AUTOSAR XML (schema 00046)
package /ComponentTypes
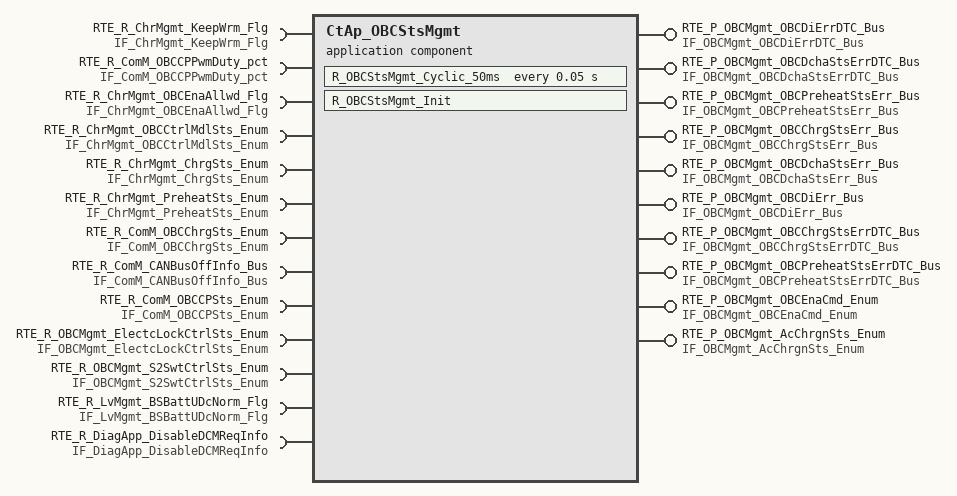
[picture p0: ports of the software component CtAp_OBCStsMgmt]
  application sw component type CtAp_OBCStsMgmt
    provide port RTE_P_OBCMgmt_OBCDiErrDTC_Bus: nonqueued-sender-com-spec{data-element=tec_OBCMgmt_OBCDiErrDTC_Bus, init-value=fields=[OBCMgmt_MonStatOBCDiErrDTC:0, OBCMgmt_MonResOBCDiErrDTC:0, OBCMgmt_ErrStatOBCDiErrDTC:0, OBCMgmt_ErrResOBCDiErrDTC:0]}, provided-interface=IF_OBCMgmt_OBCDiErrDTC_Bus
    require port RTE_R_ChrMgmt_KeepWrm_Flg: nonqueued-receiver-com-spec{data-element=tec_ChrMgmt_KeepWrm_Flg, filter=data-filter-type=ALWAYS, init-value=0}, required-interface=IF_ChrMgmt_KeepWrm_Flg
    provide port RTE_P_OBCMgmt_OBCDchaStsErrDTC_Bus: nonqueued-sender-com-spec{data-element=tec_OBCMgmt_OBCDchaStsErrDTC_Bus, init-value=fields=[OBCMgmt_MonStatOBCDchaStsErrDTC:0, OBCMgmt_MonResOBCDchaStsErrDTC:0, OBCMgmt_ErrStatOBCDchaStsErrDTC:0, OBCMgmt_ErrResOBCDchaStsErrDTC:0]}, provided-interface=IF_OBCMgmt_OBCDchaStsErrDTC_Bus
    provide port RTE_P_OBCMgmt_OBCPreheatStsErr_Bus: nonqueued-sender-com-spec{data-element=tec_OBCMgmt_OBCPreheatStsErr_Bus, init-value=fields=[OBCMgmt_MonStatOBCPreheatStsErr:0, OBCMgmt_MonResOBCPreheatStsErr:0, OBCMgmt_ErrStatOBCPreheatStsErr:0, OBCMgmt_ErrResOBCPreheatStsErr:0]}, provided-interface=IF_OBCMgmt_OBCPreheatStsErr_Bus
    require port RTE_R_ComM_OBCCPPwmDuty_pct: nonqueued-receiver-com-spec{data-element=tec_ComM_OBCCPPwmDuty_pct, filter=data-filter-type=ALWAYS, init-value=0}, required-interface=IF_ComM_OBCCPPwmDuty_pct
    provide port RTE_P_OBCMgmt_OBCChrgStsErr_Bus: nonqueued-sender-com-spec{data-element=tec_OBCMgmt_OBCChrgStsErr_Bus, init-value=fields=[OBCMgmt_MonStatOBCChrgStsErr:0, OBCMgmt_MonResOBCChrgStsErr:0, OBCMgmt_ErrStatOBCChrgStsErr:0, OBCMgmt_ErrResOBCChrgStsErr:0]}, provided-interface=IF_OBCMgmt_OBCChrgStsErr_Bus
    require port RTE_R_ChrMgmt_OBCEnaAllwd_Flg: nonqueued-receiver-com-spec{data-element=tec_ChrMgmt_OBCEnaAllwd_Flg, filter=data-filter-type=ALWAYS, init-value=0}, required-interface=IF_ChrMgmt_OBCEnaAllwd_Flg
    4 x provide port:
      RTE_P_OBCMgmt_OBCDchaStsErr_Bus: nonqueued-sender-com-spec{data-element=tec_OBCMgmt_OBCDchaStsErr_Bus, init-value=fields=[OBCMgmt_MonStatOBCDchaStsErr:0, OBCMgmt_MonResOBCDchaStsErr:0, OBCMgmt_ErrStatOBCDchaStsErr:0, OBCMgmt_ErrResOBCDchaStsErr:0]}, provided-interface=IF_OBCMgmt_OBCDchaStsErr_Bus
      RTE_P_OBCMgmt_OBCDiErr_Bus: nonqueued-sender-com-spec{data-element=tec_OBCMgmt_OBCDiErr_Bus, init-value=fields=[OBCMgmt_MonStatOBCDiErr:0, OBCMgmt_MonResOBCDiErr:0, OBCMgmt_ErrStatOBCDiErr:0, OBCMgmt_ErrResOBCDiErr:0]}, provided-interface=IF_OBCMgmt_OBCDiErr_Bus
      RTE_P_OBCMgmt_OBCChrgStsErrDTC_Bus: nonqueued-sender-com-spec{data-element=tec_OBCMgmt_OBCChrgStsErrDTC_Bus, init-value=fields=[OBCMgmt_MonStatOBCChrgStsErrDTC:0, OBCMgmt_MonResOBCChrgStsErrDTC:0, OBCMgmt_ErrStatOBCChrgStsErrDTC:0, OBCMgmt_ErrResOBCChrgStsErrDTC:0]}, provided-interface=IF_OBCMgmt_OBCChrgStsErrDTC_Bus
      RTE_P_OBCMgmt_OBCPreheatStsErrDTC_Bus: nonqueued-sender-com-spec{data-element=tec_OBCMgmt_OBCPreheatStsErrDTC_Bus, init-value=fields=[OBCMgmt_MonStatOBCPreheatStsErrDTC:0, OBCMgmt_MonResOBCPreheatStsErrDTC:0, OBCMgmt_ErrStatOBCPreheatStsErrDTC:0, OBCMgmt_ErrResOBCPreheatStsErrDTC:0]}, provided-interface=IF_OBCMgmt_OBCPreheatStsErrDTC_Bus
    require port RTE_R_ChrMgmt_OBCCtrlMdlSts_Enum: nonqueued-receiver-com-spec{data-element=tec_ChrMgmt_OBCCtrlMdlSts_Enum, filter=data-filter-type=ALWAYS, init-value=0}, required-interface=IF_ChrMgmt_OBCCtrlMdlSts_Enum
    require port RTE_R_ChrMgmt_ChrgSts_Enum: nonqueued-receiver-com-spec{data-element=tec_ChrMgmt_ChrgSts_Enum, filter=data-filter-type=ALWAYS, init-value=0}, required-interface=IF_ChrMgmt_ChrgSts_Enum
    provide port RTE_P_OBCMgmt_OBCEnaCmd_Enum: nonqueued-sender-com-spec{data-element=tec_OBCMgmt_OBCEnaCmd_Enum, init-value=0}, provided-interface=IF_OBCMgmt_OBCEnaCmd_Enum
    provide port RTE_P_OBCMgmt_AcChrgnSts_Enum: nonqueued-sender-com-spec{data-element=tec_OBCMgmt_AcChrgnSts_Enum, init-value=0}, provided-interface=IF_OBCMgmt_AcChrgnSts_Enum
    8 x require port:
      RTE_R_ChrMgmt_PreheatSts_Enum: nonqueued-receiver-com-spec{data-element=tec_ChrMgmt_PreheatSts_Enum, filter=data-filter-type=ALWAYS, init-value=0}, required-interface=IF_ChrMgmt_PreheatSts_Enum
      RTE_R_ComM_OBCChrgSts_Enum: nonqueued-receiver-com-spec{data-element=tec_ComM_OBCChrgSts_Enum, filter=data-filter-type=ALWAYS, init-value=0}, required-interface=IF_ComM_OBCChrgSts_Enum
      RTE_R_ComM_CANBusOffInfo_Bus: required-interface=IF_ComM_CANBusOffInfo_Bus
        required-com-specs:
          data-element=tec_ComM_EPTCANBusOffInfo_Bus, filter=data-filter-type=ALWAYS, init-value=fields=[ComM_MonStatEPTCANBusOffInfo:0, ComM_MonResEPTCANBusOffInfo:0, ComM_ErrStatEPTCANBusOffInfo:0, ComM_ErrResEPTCANBusOffInfo:0]
          data-element=tec_ComM_CHCANBusOffInfo_Bus, filter=data-filter-type=ALWAYS, init-value=fields=[ComM_MonStatCHCANBusOffInfo:0, ComM_MonResCHCANBusOffInfo:0, ComM_ErrStatCHCANBusOffInfo:0, ComM_ErrResCHCANBusOffInfo:0]
          data-element=tec_ComM_EPTCANBusOffDTCInfo_Bus, filter=data-filter-type=ALWAYS, init-value=fields=[ComM_MonStatEPTCANBusOffDTCInfo:0, ComM_MonResEPTCANBusOffDTCInfo:0, ComM_ErrStatEPTCANBusOffDTCInfo:0, ComM_ErrResEPTCANBusOffDTCInfo:0]
          data-element=tec_ComM_CHCANBusOffDTCInfo_Bus, filter=data-filter-type=ALWAYS, init-value=fields=[ComM_MonStatCHCANBusOffDTCInfo:0, ComM_MonResCHCANBusOffDTCInfo:0, ComM_ErrStatCHCANBusOffDTCInfo:0, ComM_ErrResCHCANBusOffDTCInfo:0]
          data-element=tec_ComM_DCCANBusOffDTCInfo_Bus, init-value=fields=[ComM_MonStatDCCANDTCBusOffInfo:0, ComM_MonResDCCANDTCBusOffInfo:0, ComM_ErrStatDCCANDTCBusOffInfo:0, ComM_ErrResDCCANDTCBusOffInfo:0]
          data-element=tec_ComM_DCCANBusOffInfo_Bus, init-value=fields=[ComM_MonStatDCCANBusOffInfo:0, ComM_MonResDCCANBusOffInfo:0, ComM_ErrStatDCCANBusOffInfo:0, ComM_ErrResDCCANBusOffInfo:0]
      RTE_R_ComM_OBCCPSts_Enum: nonqueued-receiver-com-spec{data-element=tec_ComM_OBCCPSts_Enum, filter=data-filter-type=ALWAYS, init-value=0}, required-interface=IF_ComM_OBCCPSts_Enum
      RTE_R_OBCMgmt_ElectcLockCtrlSts_Enum: nonqueued-receiver-com-spec{data-element=tec_OBCMgmt_ElectcLockCtrlSts_Enum, filter=data-filter-type=ALWAYS, init-value=0}, required-interface=IF_OBCMgmt_ElectcLockCtrlSts_Enum
      RTE_R_OBCMgmt_S2SwtCtrlSts_Enum: nonqueued-receiver-com-spec{data-element=tec_OBCMgmt_S2SwtCtrlSts_Enum, filter=data-filter-type=ALWAYS, init-value=0}, required-interface=IF_OBCMgmt_S2SwtCtrlSts_Enum
      RTE_R_LvMgmt_BSBattUDcNorm_Flg: nonqueued-receiver-com-spec{data-element=tec_LvMgmt_BSBattUDcNorm_Flg, filter=data-filter-type=ALWAYS, init-value=0}, required-interface=IF_LvMgmt_BSBattUDcNorm_Flg
      RTE_R_DiagApp_DisableDCMReqInfo: nonqueued-receiver-com-spec{data-element=tec_DiagApp_DisableDCMReqInfo, filter=data-filter-type=ALWAYS, init-value=0}, required-interface=IF_DiagApp_DisableDCMReqInfo
    behavior CtAp_OBCStsMgmt_InternalBehavior
      timing event TMT_R_OBCStsMgmt_Cyclic_50ms: start-on-event=R_OBCStsMgmt_Cyclic_50ms, period=0.05
      init event CtAp_OBCStsMgmt_InitEvent: start-on-event=R_OBCStsMgmt_Init
      runnable R_OBCStsMgmt_Cyclic_50ms
        data-receive-point-by-arguments:
          13 x access:
            REC_RTE_R_ChrMgmt_ChrgSts_Enum_tec_ChrMgmt_ChrgSts_Enum: accessed-variable=RTE_R_ChrMgmt_ChrgSts_Enum.tec_ChrMgmt_ChrgSts_Enum
            REC_RTE_R_ChrMgmt_KeepWrm_Flg_tec_ChrMgmt_KeepWrm_Flg: accessed-variable=RTE_R_ChrMgmt_KeepWrm_Flg.tec_ChrMgmt_KeepWrm_Flg
            REC_RTE_R_ChrMgmt_OBCCtrlMdlSts_Enum_tec_ChrMgmt_OBCCtrlMdlSts_Enum: accessed-variable=RTE_R_ChrMgmt_OBCCtrlMdlSts_Enum.tec_ChrMgmt_OBCCtrlMdlSts_Enum
            REC_RTE_R_ChrMgmt_OBCEnaAllwd_Flg_tec_ChrMgmt_OBCEnaAllwd_Flg: accessed-variable=RTE_R_ChrMgmt_OBCEnaAllwd_Flg.tec_ChrMgmt_OBCEnaAllwd_Flg
            REC_RTE_R_ChrMgmt_PreheatSts_Enum_tec_ChrMgmt_PreheatSts_Enum: accessed-variable=RTE_R_ChrMgmt_PreheatSts_Enum.tec_ChrMgmt_PreheatSts_Enum
            REC_RTE_R_ComM_CANBusOffInfo_Bus_tec_ComM_EPTCANBusOffInfo_Bus: accessed-variable=RTE_R_ComM_CANBusOffInfo_Bus.tec_ComM_EPTCANBusOffInfo_Bus
            REC_RTE_R_ComM_OBCCPPwmDuty_pct_tec_ComM_OBCCPPwmDuty_pct: accessed-variable=RTE_R_ComM_OBCCPPwmDuty_pct.tec_ComM_OBCCPPwmDuty_pct
            REC_RTE_R_ComM_OBCCPSts_Enum_tec_ComM_OBCCPSts_Enum: accessed-variable=RTE_R_ComM_OBCCPSts_Enum.tec_ComM_OBCCPSts_Enum
            REC_RTE_R_ComM_OBCChrgSts_Enum_tec_ComM_OBCChrgSts_Enum: accessed-variable=RTE_R_ComM_OBCChrgSts_Enum.tec_ComM_OBCChrgSts_Enum
            REC_RTE_R_OBCMgmt_ElectcLockCtrlSts_Enum_tec_OBCMgmt_ElectcLockCtrlSts_Enum: accessed-variable=RTE_R_OBCMgmt_ElectcLockCtrlSts_Enum.tec_OBCMgmt_ElectcLockCtrlSts_Enum
            REC_RTE_R_LvMgmt_BSBattUDcNorm_Flg_tec_LvMgmt_BSBattUDcNorm_Flg: accessed-variable=RTE_R_LvMgmt_BSBattUDcNorm_Flg.tec_LvMgmt_BSBattUDcNorm_Flg
            REC_RTE_R_OBCMgmt_S2SwtCtrlSts_Enum_tec_OBCMgmt_S2SwtCtrlSts_Enum: accessed-variable=RTE_R_OBCMgmt_S2SwtCtrlSts_Enum.tec_OBCMgmt_S2SwtCtrlSts_Enum
            REC_RTE_R_DiagApp_DisableDCMReqInfo_tec_DiagApp_DisableDCMReqInfo: accessed-variable=RTE_R_DiagApp_DisableDCMReqInfo.tec_DiagApp_DisableDCMReqInfo
        data-send-points:
          10 x access:
            SEND_RTE_P_OBCMgmt_AcChrgnSts_Enum_tec_OBCMgmt_AcChrgnSts_Enum: accessed-variable=RTE_P_OBCMgmt_AcChrgnSts_Enum.tec_OBCMgmt_AcChrgnSts_Enum
            SEND_RTE_P_OBCMgmt_OBCChrgStsErrDTC_Bus_tec_OBCMgmt_OBCChrgStsErrDTC_Bus: accessed-variable=RTE_P_OBCMgmt_OBCChrgStsErrDTC_Bus.tec_OBCMgmt_OBCChrgStsErrDTC_Bus
            SEND_RTE_P_OBCMgmt_OBCChrgStsErr_Bus_tec_OBCMgmt_OBCChrgStsErr_Bus: accessed-variable=RTE_P_OBCMgmt_OBCChrgStsErr_Bus.tec_OBCMgmt_OBCChrgStsErr_Bus
            SEND_RTE_P_OBCMgmt_OBCDchaStsErrDTC_Bus_tec_OBCMgmt_OBCDchaStsErrDTC_Bus: accessed-variable=RTE_P_OBCMgmt_OBCDchaStsErrDTC_Bus.tec_OBCMgmt_OBCDchaStsErrDTC_Bus
            SEND_RTE_P_OBCMgmt_OBCDchaStsErr_Bus_tec_OBCMgmt_OBCDchaStsErr_Bus: accessed-variable=RTE_P_OBCMgmt_OBCDchaStsErr_Bus.tec_OBCMgmt_OBCDchaStsErr_Bus
            SEND_RTE_P_OBCMgmt_OBCDiErrDTC_Bus_tec_OBCMgmt_OBCDiErrDTC_Bus: accessed-variable=RTE_P_OBCMgmt_OBCDiErrDTC_Bus.tec_OBCMgmt_OBCDiErrDTC_Bus
            SEND_RTE_P_OBCMgmt_OBCDiErr_Bus_tec_OBCMgmt_OBCDiErr_Bus: accessed-variable=RTE_P_OBCMgmt_OBCDiErr_Bus.tec_OBCMgmt_OBCDiErr_Bus
            SEND_RTE_P_OBCMgmt_OBCEnaCmd_Enum_tec_OBCMgmt_OBCEnaCmd_Enum: accessed-variable=RTE_P_OBCMgmt_OBCEnaCmd_Enum.tec_OBCMgmt_OBCEnaCmd_Enum
            SEND_RTE_P_OBCMgmt_OBCPreheatStsErrDTC_Bus_tec_OBCMgmt_OBCPreheatStsErrDTC_Bus: accessed-variable=RTE_P_OBCMgmt_OBCPreheatStsErrDTC_Bus.tec_OBCMgmt_OBCPreheatStsErrDTC_Bus
            SEND_RTE_P_OBCMgmt_OBCPreheatStsErr_Bus_tec_OBCMgmt_OBCPreheatStsErr_Bus: accessed-variable=RTE_P_OBCMgmt_OBCPreheatStsErr_Bus.tec_OBCMgmt_OBCPreheatStsErr_Bus
      runnable R_OBCStsMgmt_Init
  swc implementation CtAp_OBCStsMgmt_Implementation: behavior=CtAp_OBCStsMgmt_InternalBehavior
